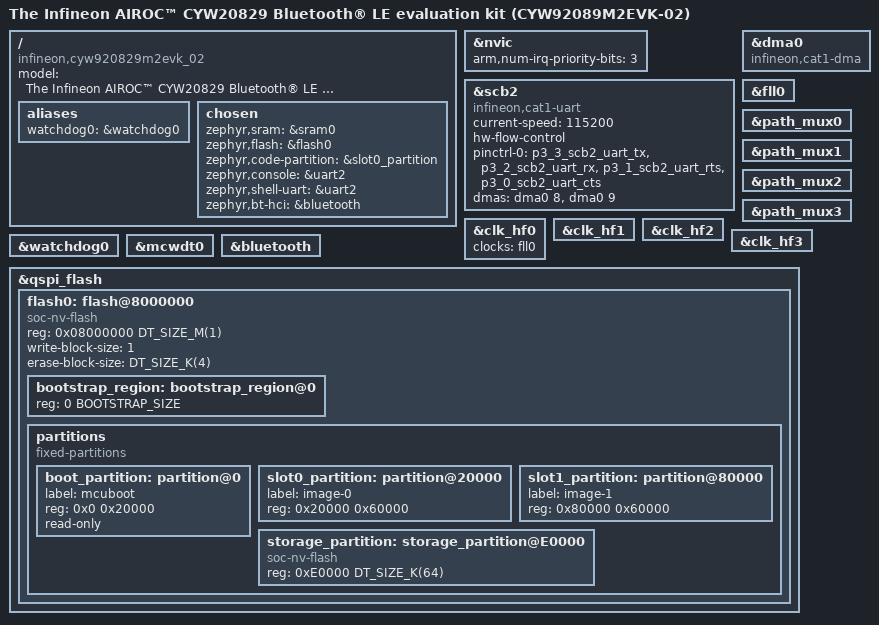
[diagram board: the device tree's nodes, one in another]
/*
 * Copyright (c) 2024 Cypress Semiconductor Corporation.
 * SPDX-License-Identifier: Apache-2.0
 */

/dts-v1/;
#include <arm/infineon/cat1b/mpns/CYW20829B0LKML.dtsi>
#include <arm/infineon/cat1b/cyw20829/system_clocks.dtsi>
#include "cyw920829m2evk_02-common.dtsi"
#include "cyw920829m2evk_02-pinctrl.dtsi"

/ {
	model = "The Infineon AIROC™ CYW20829 Bluetooth® LE evaluation kit (CYW92089M2EVK-02)";
	compatible = "infineon,cyw920829m2evk_02", "infineon,CYW20829";

	aliases {
		watchdog0 = &watchdog0;
	};

	chosen {
		zephyr,sram = &sram0;
		zephyr,flash = &flash0;
		zephyr,code-partition = &slot0_partition;
		zephyr,console = &uart2;
		zephyr,shell-uart = &uart2;
		zephyr,bt-hci = &bluetooth;
	};
};

&nvic {
	arm,num-irq-priority-bits = <3>;
};

uart2: &scb2 {
	compatible = "infineon,cat1-uart";
	status = "okay";
	current-speed = <115200>;
	hw-flow-control;

	pinctrl-0 = <&p3_3_scb2_uart_tx &p3_2_scb2_uart_rx &p3_1_scb2_uart_rts &p3_0_scb2_uart_cts>;
	pinctrl-names = "default";

	dmas = <&dma0 8>, <&dma0 9>;
	dma-names = "tx", "rx";
};

&dma0 {
	#address-cells = <1>;
	#size-cells = <0>;
	compatible = "infineon,cat1-dma";
	status = "okay";
};

&fll0 {
	status = "okay";
};

&path_mux0 {
	status = "okay";
};

&path_mux1 {
	status = "okay";
};

&path_mux2 {
	status = "okay";
};

&path_mux3 {
	status = "okay";
};

&clk_hf0 {
	status = "okay";
	clocks = <&fll0>;
};

&clk_hf1 {
	status = "okay";
};

&clk_hf2 {
	status = "okay";
};

&clk_hf3 {
	status = "okay";
};

&watchdog0 {
	status = "okay";
};

&mcwdt0 {
	status = "okay";
};

&bluetooth {
	status = "okay";
};

&qspi_flash {
	flash0: flash@8000000 {
		compatible = "soc-nv-flash";
		reg = <0x08000000 DT_SIZE_M(1)>;
		write-block-size = <1>;
		erase-block-size = <DT_SIZE_K(4)>;
		#address-cells = <1>;
		#size-cells = <1>;

		/* Keep bootstrap_region node to know size, finally it will
		 * locate on beginning of code-partition. The BootROM copies
		 * bootstrap application in RAM and launches it.
		 */
		bootstrap_region: bootstrap_region@0 {
			reg = <0 BOOTSTRAP_SIZE>;
		};

		partitions {
			compatible = "fixed-partitions";
			#address-cells = <1>;
			#size-cells = <1>;

			boot_partition: partition@0 {
				label = "mcuboot";
				reg = <0x0 0x20000>;
				read-only;
			};

			slot0_partition: partition@20000 {
				label = "image-0";
				reg = <0x20000 0x60000>;
			};

			slot1_partition: partition@80000 {
				label = "image-1";
				reg = <0x80000 0x60000>;
			};

			storage_partition: storage_partition@E0000 {
				compatible = "soc-nv-flash";
				reg = <0xE0000 DT_SIZE_K(64)>;
			};
		};
	};
};
